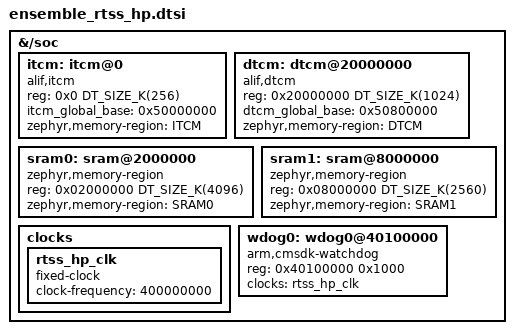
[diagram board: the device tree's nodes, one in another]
/* Copyright (c) 2024 Alif Semiconductor
 *
 * SPDX-License-Identifier: Apache-2.0
 */
#include <arm/armv8.1-m.dtsi>
#include <mem.h>
&{/soc} {
	itcm: itcm@0 {
		compatible = "alif,itcm";
		reg = <0x0 DT_SIZE_K(256)>;
		itcm_global_base = <0x50000000>;
		zephyr,memory-region = "ITCM";
	};
	dtcm: dtcm@20000000 {
		compatible = "alif,dtcm";
		reg = <0x20000000 DT_SIZE_K(1024)>;
		dtcm_global_base = <0x50800000>;
		zephyr,memory-region = "DTCM";
	};
	sram0: sram@2000000 {
		compatible = "zephyr,memory-region","mmio-sram";
		reg = <0x02000000 DT_SIZE_K(4096)>;
		zephyr,memory-region = "SRAM0";
	};
	sram1: sram@8000000 {
		compatible = "zephyr,memory-region","mmio-sram";
		reg = <0x08000000 DT_SIZE_K(2560)>;
		zephyr,memory-region = "SRAM1";
	};
	clocks {
		rtss_hp_clk: rtss_hp_clk {
			compatible = "fixed-clock";
			clock-frequency = <400000000>;
			#clock-cells = <0>;
		};
	};
	wdog0: wdog0@40100000{
		compatible = "arm,cmsdk-watchdog";
		reg = <0x40100000 0x1000>;
		clocks = <&rtss_hp_clk>;
		status = "okay";
	};
};
